# ATSAML10D16A device description
Architecture: CORTEX-M23; Family: SAML; Series: SAML10
Registers are 32-bit, read-write, reset 0x0 unless marked. A register's access mark holds for its fields unless they carry their own. Offsets are from the block's base; [hi:lo] are bit positions; {n}, {i} and the like mark numbered series; 'fields as' and 'values as' point back to an identical list.

## BOCOR_FUSES — Non-Volatile Fuses
Instances: BOCOR_FUSES 0x0080C000 in fuses
0x04 BOCOR_WORD_1 reset 0xFFFFFF00 — BOCOR Page Word 1
  [7:0] IDAU_BOOTPROT — Boot Protection
{0x0+4i} BOCOR_WORD_{i} reset 0xFFFFFFFF (i=16..19) — BOCOR Page Word {i}
  [31:0] BOOTROM_CRCKEY_{i-16} — CRC Key bits {32i-481}:{32i-512}

## SW_CALIB_FUSES — Non-Volatile Fuses
Instances: SW_CALIB_FUSES 0x00806020 in fuses
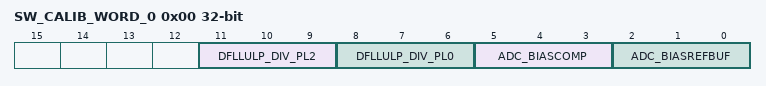
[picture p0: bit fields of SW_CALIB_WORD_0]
0x00 SW_CALIB_WORD_0 ro reset not defined — SW_CALIB Page Word 0
  [11:9] DFLLULP_DIV_PL2 — DFLLULP DIV at PL2
  [8:6] DFLLULP_DIV_PL0 — DFLLULP DIV at PL0
  [5:3] ADC_BIASCOMP — ADC Comparator Scaling
  [2:0] ADC_BIASREFBUF — ADC Bias Reference Buffer Scaling

## TEMP_LOG_FUSES — Non-Volatile Fuses
Instances: TEMP_LOG_FUSES 0x00806038 in fuses
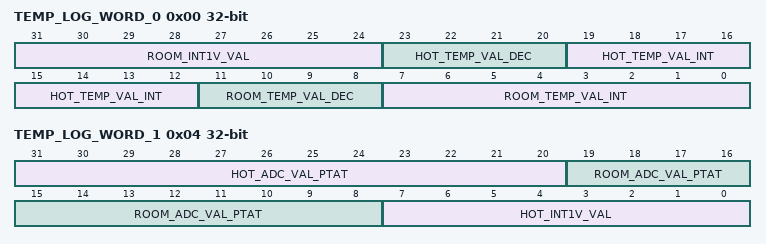
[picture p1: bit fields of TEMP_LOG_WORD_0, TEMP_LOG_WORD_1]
0x00 TEMP_LOG_WORD_0 ro reset not defined — TEMP_LOG Page Word 0
  [31:24] ROOM_INT1V_VAL — 2's complement of the internal 1V reference drift at room temperature (versus a 1.0 centered value)
  [23:20] HOT_TEMP_VAL_DEC — Decimal part of hot temperature
  [19:12] HOT_TEMP_VAL_INT — Integer part of hot temperature in oC
  [11:8] ROOM_TEMP_VAL_DEC — Decimal part of room temperature
  [7:0] ROOM_TEMP_VAL_INT — Integer part of room temperature in oC
0x04 TEMP_LOG_WORD_1 ro reset not defined — TEMP_LOG Page Word 1
  [31:20] HOT_ADC_VAL_PTAT — 12-bit ADC conversion at hot temperature PTAT
  [19:8] ROOM_ADC_VAL_PTAT — 12-bit ADC conversion at room temperature PTAT
  [7:0] HOT_INT1V_VAL — 2's complement of the internal 1V reference drift at hot temperature (versus a 1.0 centered value)

## USER_FUSES — Non-Volatile Fuses
Instances: USER_FUSES 0x00804000 in fuses
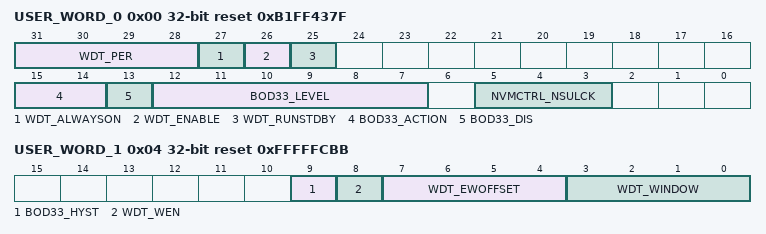
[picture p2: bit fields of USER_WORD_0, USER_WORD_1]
0x00 USER_WORD_0 reset 0xB1FF437F — USER Page Word 0
  [31:28] WDT_PER — WDT Period
    0=CYC8 (8 clock cycles); 1=CYC16 (16 clock cycles); 2=CYC32 (32 clock cycles); 3=CYC64 (64 clock cycles); 4=CYC128 (128 clock cycles); 5=CYC256 (256 clock cycles); 6=CYC512 (512 clock cycles); 7=CYC1024 (1024 clock cycles); 8=CYC2048 (2048 clock cycles); 9=CYC4096 (4096 clock cycles); 10=CYC8192 (8192 clock cycles); 11=CYC16384 (16384 clock cycles)
  [27] WDT_ALWAYSON
  [26] WDT_ENABLE
  [25] WDT_RUNSTDBY — WDT Run During Standby
  [15:14] BOD33_ACTION
    0=NONE (No action); 1=RESET (The BOD33 generates a reset); 2=INT (The BOD33 generates an interrupt)
  [13] BOD33_DIS — BOD33 Disable
  [12:7] BOD33_LEVEL — BOD33 threshold Level
  [5:3] NVMCTRL_NSULCK — NVM Non-Secure Region Locks
0x04 USER_WORD_1 reset 0xFFFFFCBB — USER Page Word 1
  [9] BOD33_HYST — BOD33 Hysteresis
  [8] WDT_WEN — WDT Window Mode Enable
  [7:4] WDT_EWOFFSET — WDT Early Warning Offset
    values as USER_WORD_0.WDT_PER
  [3:0] WDT_WINDOW
    values as USER_WORD_0.WDT_PER

## OSC32KCTRL — 32k Oscillators Control
Instances: OSC32KCTRL 0x40001400
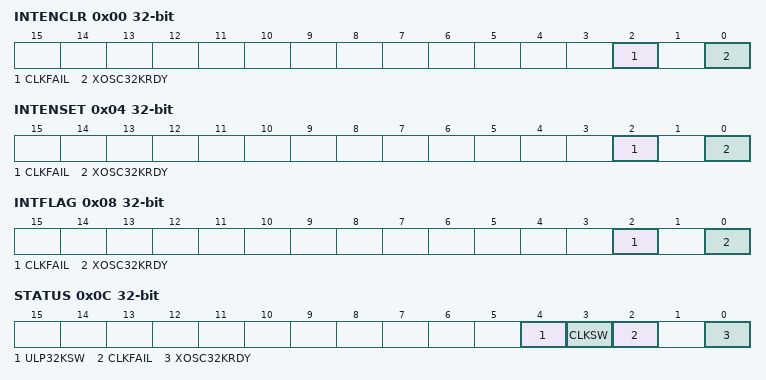
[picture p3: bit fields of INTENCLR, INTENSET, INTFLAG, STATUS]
0x00 INTENCLR (atomic clear) — Interrupt Enable Clear
  [2] CLKFAIL — XOSC32K Clock Failure Detector Interrupt Enable
  [0] XOSC32KRDY — XOSC32K Ready Interrupt Enable
0x04 INTENSET (atomic set) — Interrupt Enable Set
  fields as INTENCLR
0x08 INTFLAG (atomic clear) — Interrupt Flag Status and Clear
  [2] CLKFAIL — XOSC32K Clock Failure Detector
  [0] XOSC32KRDY — XOSC32K Ready
0x0C STATUS ro — Power and Clocks Status
  [4] ULP32KSW — OSCULP32K Clock Switch
  [3] CLKSW — XOSC32K Clock switch
  [2] CLKFAIL — XOSC32K Clock Failure Detector
  [0] XOSC32KRDY — XOSC32K Ready
0x10 RTCCTRL 8-bit — RTC Clock Selection
  [2:0] RTCSEL
    0=ULP1K (1.024kHz from 32kHz internal ULP oscillator); 1=ULP32K (32.768kHz from 32kHz internal ULP oscillator); 4=XOSC1K (1.024kHz from 32.768kHz external oscillator); 5=XOSC32K (32.768kHz from 32.768kHz external crystal oscillator)
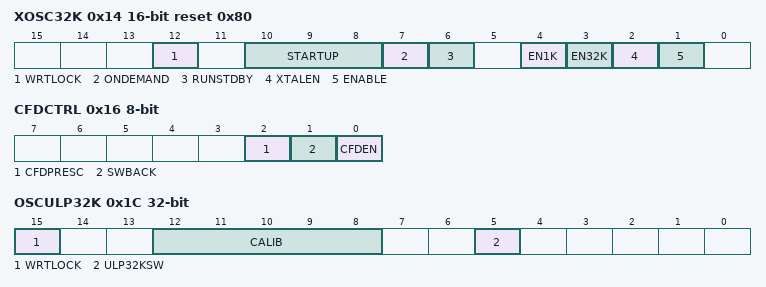
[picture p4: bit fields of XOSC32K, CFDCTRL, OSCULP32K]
0x14 XOSC32K 16-bit reset 0x80 — 32kHz External Crystal Oscillator (XOSC32K) Control
  [12] WRTLOCK — Write Lock
  [10:8] STARTUP — Oscillator Start-Up Time
    0=CYCLE1 (0.122 ms); 1=CYCLE32 (1.068 ms); 2=CYCLE2048 (62.6 ms); 3=CYCLE4096 (125 ms); 4=CYCLE16384 (500 ms); 5=CYCLE32768 (1000 ms); 6=CYCLE65536 (2000 ms); 7=CYCLE131072 (4000 ms)
  [7] ONDEMAND — On Demand Control
  [6] RUNSTDBY — Run in Standby
  [4] EN1K — 1kHz Output Enable
  [3] EN32K — 32kHz Output Enable
  [2] XTALEN — Crystal Oscillator Enable
  [1] ENABLE — Oscillator Enable
0x16 CFDCTRL 8-bit — Clock Failure Detector Control
  [2] CFDPRESC — Clock Failure Detector Prescaler
  [1] SWBACK — Clock Switch Back
  [0] CFDEN — Clock Failure Detector Enable
0x17 EVCTRL 8-bit — Event Control
  [0] CLKFAILEO — Clock Failure Detector Event Output Enable
0x1C OSCULP32K — 32kHz Ultra Low Power Internal Oscillator (OSCULP32K) Control
  [15] WRTLOCK — Write Lock
  [12:8] CALIB — Oscillator Calibration
  [5] ULP32KSW — OSCULP32K Clock Switch Enable

## Notices in the file
Copyright (c) 2019 Microchip Technology Inc.
SPDX-License-Identifier: Apache-2.0
Licensed under the Apache License, Version 2.0 (the "License");
you may not use this file except in compliance with the License.
You may obtain a copy of the License at
http://www.apache.org/licenses/LICENSE-2.0
Unless required by applicable law or agreed to in writing, software
distributed under the License is distributed on an "AS IS" BASIS,
WITHOUT WARRANTIES OR CONDITIONS OF ANY KIND, either express or implied.
See the License for the specific language governing permissions and
limitations under the License.
